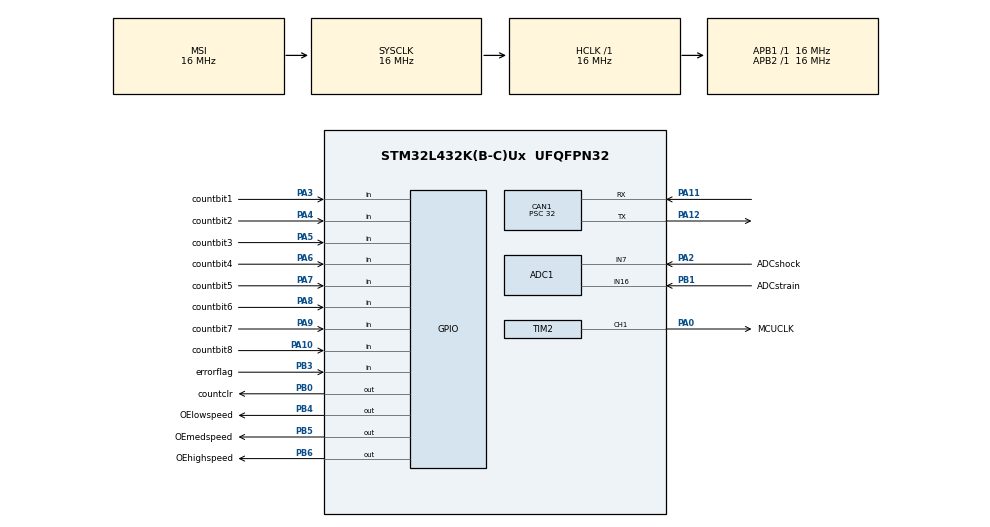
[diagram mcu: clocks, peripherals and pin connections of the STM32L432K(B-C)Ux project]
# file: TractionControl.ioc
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Mcu.Family=STM32L4
RCC.CortexFreq_Value=16000000
PA0.GPIO_Label=MCUCLK
PA11.Mode=Master
PA6.GPIO_Label=countbit4
PB0.GPIO_Label=countclr
PB6.GPIO_Label=OEhighspeed
ProjectManager.StackSize=0x400
PB3\ (JTDO-TRACESWO).Signal=GPIO_Input
SH.ADCx_IN16.0=ADC1_IN16,IN16-Single-Ended
PA14\ (JTCK-SWCLK).Signal=SYS_JTCK-SWCLK
PA12.Signal=CAN1_TX
TIM15.Prescaler=10000
RCC.HCLKFreq_Value=16000000
RCC.APB2TimFreq_Value=16000000
PB6.Signal=GPIO_Output
RCC.AHBFreq_Value=16000000
ADC1.Channel-0\#ChannelRegularConversion=ADC_CHANNEL_7
RCC.HSE_VALUE=8000000
VP_SYS_VS_tim1.Mode=TIM1
PB1.GPIO_Label=ADCstrain
PA10.GPIO_Label=countbit8
PA8.Signal=GPIO_Input
TIM2.Channel-PWM\ Generation1\ CH1=TIM_CHANNEL_1
ADC1.SamplingTime-0\#ChannelRegularConversion=ADC_SAMPLETIME_2CYCLES_5
PA0.Signal=S_TIM2_CH1
CAN1.Prescaler=32
Mcu.Package=UFQFPN32
PA6.Signal=GPIO_Input
PB1.Signal=ADCx_IN16
NVIC.TimeBase=TIM1_UP_TIM16_IRQn
PA2.GPIO_Label=ADCshock
NVIC.TimeBaseIP=TIM1
PA10.Signal=GPIO_Input
PB5.GPIO_Label=OEmedspeed
RCC.APB1TimFreq_Value=16000000
PA13\ (JTMS-SWDIO).Signal=SYS_JTMS-SWDIO
PA4.GPIO_Label=countbit2
RCC.MSIClockRange=RCC_MSIRANGE_8
RCC.HSI48_VALUE=48000000
PA3.Signal=GPIO_Input
CAN1.CalculateTimeQuantum=2000.0
RCC.MSI_VALUE=16000000
PA14\ (JTCK-SWCLK).Mode=Serial_Wire
SH.S_TIM2_CH1.0=TIM2_CH1,PWM Generation1 CH1
ADC1.Rank-0\#ChannelRegularConversion=1
ADC1.OffsetNumber-0\#ChannelRegularConversion=ADC_OFFSET_NONE
PA9.GPIO_Label=countbit7
PB3\ (JTDO-TRACESWO).GPIO_Label=errorflag
TIM2.Pulse-PWM\ Generation1\ CH1=1
PA8.GPIO_Label=countbit6
CAN1.BS2=CAN_BS2_2TQ
ProjectManager.TargetToolchain=SW4STM32
SH.ADCx_IN7.0=ADC1_IN7,IN7-Single-Ended
PA9.Signal=GPIO_Input
RCC.USBFreq_Value=64000000
RCC.LSE_VALUE=32768
PA5.Signal=GPIO_Input
NVIC.TIM1_BRK_TIM15_IRQn=true\:0\:0\:false\:false\:true\:true\:true
board=custom
RCC.VCOOutputFreq_Value=128000000
RCC.APB2Freq_Value=16000000
RCC.ADCFreq_Value=64000000
TIM2.Period=1
Mcu.Name=STM32L432K(B-C)Ux
PA2.Signal=ADCx_IN7
CAN1.SJW=CAN_SJW_2TQ
PA13\ (JTMS-SWDIO).Mode=Serial_Wire
PA4.Signal=GPIO_Input
RCC.SYSCLKFreq_VALUE=16000000
PB5.Signal=GPIO_Output
PA7.GPIO_Label=countbit5
ADC1.master=1
PA12.Mode=Master
PA5.GPIO_Label=countbit3
PA11.Signal=CAN1_RX
VP_TIM15_VS_ClockSourceINT.Mode=Internal
ProjectManager.HeapSize=0x200
RCC.HSI_VALUE=16000000
NVIC.TIM1_UP_TIM16_IRQn=true\:0\:0\:false\:false\:true\:false\:true
NVIC.PriorityGroup=NVIC_PRIORITYGROUP_4
ADC1.NbrOfConversionFlag=1
PB4\ (NJTRST).GPIO_Label=OElowspeed
RCC.APB1Freq_Value=16000000
PB0.Signal=GPIO_Output
PA3.GPIO_Label=countbit1
PA7.Signal=GPIO_Input
PB4\ (NJTRST).Signal=GPIO_Output

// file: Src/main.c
/* USER CODE BEGIN Header */
/**
  ******************************************************************************
  * @file           : main.c
  * @brief          : Main program body
  ******************************************************************************
  ** This notice applies to any and all portions of this file
  * that are not between comment pairs USER CODE BEGIN and
  * USER CODE END. Other portions of this file, whether
  * inserted by the user or by software development tools
  * are owned by their respective copyright owners.
  *
  * COPYRIGHT(c) 2020 STMicroelectronics
  *
  * Redistribution and use in source and binary forms, with or without modification,
  * are permitted provided that the following conditions are met:
  *   1. Redistributions of source code must retain the above copyright notice,
  *      this list of conditions and the following disclaimer.
  *   2. Redistributions in binary form must reproduce the above copyright notice,
  *      this list of conditions and the following disclaimer in the documentation
  *      and/or other materials provided with the distribution.
  *   3. Neither the name of STMicroelectronics nor the names of its contributors
  *      may be used to endorse or promote products derived from this software
  *      without specific prior written permission.
  *
  * THIS SOFTWARE IS PROVIDED BY THE COPYRIGHT HOLDERS AND CONTRIBUTORS "AS IS"
  * AND ANY EXPRESS OR IMPLIED WARRANTIES, INCLUDING, BUT NOT LIMITED TO, THE
  * IMPLIED WARRANTIES OF MERCHANTABILITY AND FITNESS FOR A PARTICULAR PURPOSE ARE
  * DISCLAIMED. IN NO EVENT SHALL THE COPYRIGHT HOLDER OR CONTRIBUTORS BE LIABLE
  * FOR ANY DIRECT, INDIRECT, INCIDENTAL, SPECIAL, EXEMPLARY, OR CONSEQUENTIAL
  * DAMAGES (INCLUDING, BUT NOT LIMITED TO, PROCUREMENT OF SUBSTITUTE GOODS OR
  * SERVICES; LOSS OF USE, DATA, OR PROFITS; OR BUSINESS INTERRUPTION) HOWEVER
  * CAUSED AND ON ANY THEORY OF LIABILITY, WHETHER IN CONTRACT, STRICT LIABILITY,
  * OR TORT (INCLUDING NEGLIGENCE OR OTHERWISE) ARISING IN ANY WAY OUT OF THE USE
  * OF THIS SOFTWARE, EVEN IF ADVISED OF THE POSSIBILITY OF SUCH DAMAGE.
  *
  ******************************************************************************
  */
/* USER CODE END Header */

#include "main.h"

/* USER CODE BEGIN Includes */
#include "tc.h"
/* USER CODE END Includes */

ADC_HandleTypeDef hadc1;

CAN_HandleTypeDef hcan1;

TIM_HandleTypeDef htim2;
TIM_HandleTypeDef htim15;

void SystemClock_Config(void);
static void MX_GPIO_Init(void);
static void MX_TIM2_Init(void);
static void MX_CAN1_Init(void);
static void MX_ADC1_Init(void);
static void MX_TIM15_Init(void);

int main(void)
{

  /* MCU Configuration--------------------------------------------------------*/

  /* Reset of all peripherals, Initializes the Flash interface and the Systick. */
  HAL_Init();

  /* Configure the system clock */
  SystemClock_Config();

  /* Initialize all configured peripherals */
  MX_GPIO_Init();
  MX_TIM2_Init();
  MX_CAN1_Init();
  MX_ADC1_Init();
  MX_TIM15_Init();
  /* USER CODE BEGIN 2 */

  // Clear the binary counter
  HAL_GPIO_WritePin(countclr_GPIO_Port, countclr_Pin, 1);
  HAL_Delay(2);
  HAL_GPIO_WritePin(countclr_GPIO_Port, countclr_Pin, 0);
  HAL_GPIO_WritePin(OElowspeed_GPIO_Port, OElowspeed_Pin, 1);

  // Initialize and start timer 2
  tim2Setup();
  tim7Setup();
  tcLoop();
  /* USER CODE END 2 */

  /* Infinite loop */
  /* USER CODE BEGIN WHILE */
  while (1)
  {
    // We will just be chilling here until timer 15 throws an interrupt and tcLoop() handles it
    /* USER CODE END WHILE */

  }
}

void SystemClock_Config(void)
{
  RCC_OscInitTypeDef RCC_OscInitStruct = {0};
  RCC_ClkInitTypeDef RCC_ClkInitStruct = {0};
  RCC_PeriphCLKInitTypeDef PeriphClkInit = {0};

  /**Initializes the CPU, AHB and APB busses clocks
  */
  RCC_OscInitStruct.OscillatorType = RCC_OSCILLATORTYPE_MSI;
  RCC_OscInitStruct.MSIState = RCC_MSI_ON;
  RCC_OscInitStruct.MSICalibrationValue = 0;
  RCC_OscInitStruct.MSIClockRange = RCC_MSIRANGE_8;
  RCC_OscInitStruct.PLL.PLLState = RCC_PLL_NONE;
  if (HAL_RCC_OscConfig(&RCC_OscInitStruct) != HAL_OK)
  {
    Error_Handler();
  }
  /**Initializes the CPU, AHB and APB busses clocks
  */
  RCC_ClkInitStruct.ClockType = RCC_CLOCKTYPE_HCLK|RCC_CLOCKTYPE_SYSCLK
                              |RCC_CLOCKTYPE_PCLK1|RCC_CLOCKTYPE_PCLK2;
  RCC_ClkInitStruct.SYSCLKSource = RCC_SYSCLKSOURCE_MSI;
  RCC_ClkInitStruct.AHBCLKDivider = RCC_SYSCLK_DIV1;
  RCC_ClkInitStruct.APB1CLKDivider = RCC_HCLK_DIV1;
  RCC_ClkInitStruct.APB2CLKDivider = RCC_HCLK_DIV1;

  if (HAL_RCC_ClockConfig(&RCC_ClkInitStruct, FLASH_LATENCY_0) != HAL_OK)
  {
    Error_Handler();
  }
  PeriphClkInit.PeriphClockSelection = RCC_PERIPHCLK_ADC;
  PeriphClkInit.AdcClockSelection = RCC_ADCCLKSOURCE_PLLSAI1;
  PeriphClkInit.PLLSAI1.PLLSAI1Source = RCC_PLLSOURCE_MSI;
  PeriphClkInit.PLLSAI1.PLLSAI1M = 1;
  PeriphClkInit.PLLSAI1.PLLSAI1N = 8;
  PeriphClkInit.PLLSAI1.PLLSAI1P = RCC_PLLP_DIV7;
  PeriphClkInit.PLLSAI1.PLLSAI1Q = RCC_PLLQ_DIV2;
  PeriphClkInit.PLLSAI1.PLLSAI1R = RCC_PLLR_DIV2;
  PeriphClkInit.PLLSAI1.PLLSAI1ClockOut = RCC_PLLSAI1_ADC1CLK;
  if (HAL_RCCEx_PeriphCLKConfig(&PeriphClkInit) != HAL_OK)
  {
    Error_Handler();
  }
  /**Configure the main internal regulator output voltage
  */
  if (HAL_PWREx_ControlVoltageScaling(PWR_REGULATOR_VOLTAGE_SCALE1) != HAL_OK)
  {
    Error_Handler();
  }
}

static void MX_ADC1_Init(void)
{

  ADC_ChannelConfTypeDef sConfig = {0};

  /**Common config
  */
  hadc1.Instance = ADC1;
  hadc1.Init.ClockPrescaler = ADC_CLOCK_ASYNC_DIV1;
  hadc1.Init.Resolution = ADC_RESOLUTION_12B;
  hadc1.Init.DataAlign = ADC_DATAALIGN_RIGHT;
  hadc1.Init.ScanConvMode = ADC_SCAN_DISABLE;
  hadc1.Init.EOCSelection = ADC_EOC_SINGLE_CONV;
  hadc1.Init.LowPowerAutoWait = DISABLE;
  hadc1.Init.ContinuousConvMode = DISABLE;
  hadc1.Init.NbrOfConversion = 1;
  hadc1.Init.DiscontinuousConvMode = DISABLE;
  hadc1.Init.ExternalTrigConv = ADC_SOFTWARE_START;
  hadc1.Init.ExternalTrigConvEdge = ADC_EXTERNALTRIGCONVEDGE_NONE;
  hadc1.Init.DMAContinuousRequests = DISABLE;
  hadc1.Init.Overrun = ADC_OVR_DATA_PRESERVED;
  hadc1.Init.OversamplingMode = DISABLE;
  if (HAL_ADC_Init(&hadc1) != HAL_OK)
  {
    Error_Handler();
  }
  /**Configure Regular Channel
  */
  sConfig.Channel = ADC_CHANNEL_7;
  sConfig.Rank = ADC_REGULAR_RANK_1;
  sConfig.SamplingTime = ADC_SAMPLETIME_2CYCLES_5;
  sConfig.SingleDiff = ADC_SINGLE_ENDED;
  sConfig.OffsetNumber = ADC_OFFSET_NONE;
  sConfig.Offset = 0;
  if (HAL_ADC_ConfigChannel(&hadc1, &sConfig) != HAL_OK)
  {
    Error_Handler();
  }

}

static void MX_CAN1_Init(void)
{

  hcan1.Instance = CAN1;
  hcan1.Init.Prescaler = 32;
  hcan1.Init.Mode = CAN_MODE_NORMAL;
  hcan1.Init.SyncJumpWidth = CAN_SJW_2TQ;
  hcan1.Init.TimeSeg1 = CAN_BS1_1TQ;
  hcan1.Init.TimeSeg2 = CAN_BS2_2TQ;
  hcan1.Init.TimeTriggeredMode = DISABLE;
  hcan1.Init.AutoBusOff = DISABLE;
  hcan1.Init.AutoWakeUp = DISABLE;
  hcan1.Init.AutoRetransmission = DISABLE;
  hcan1.Init.ReceiveFifoLocked = DISABLE;
  hcan1.Init.TransmitFifoPriority = DISABLE;
  if (HAL_CAN_Init(&hcan1) != HAL_OK)
  {
    Error_Handler();
  }

}

static void MX_TIM2_Init(void)
{

  TIM_MasterConfigTypeDef sMasterConfig = {0};
  TIM_OC_InitTypeDef sConfigOC = {0};

  htim2.Instance = TIM2;
  htim2.Init.Prescaler = 0;
  htim2.Init.CounterMode = TIM_COUNTERMODE_UP;
  htim2.Init.Period = 1;
  htim2.Init.ClockDivision = TIM_CLOCKDIVISION_DIV1;
  htim2.Init.AutoReloadPreload = TIM_AUTORELOAD_PRELOAD_DISABLE;
  if (HAL_TIM_PWM_Init(&htim2) != HAL_OK)
  {
    Error_Handler();
  }
  sMasterConfig.MasterOutputTrigger = TIM_TRGO_RESET;
  sMasterConfig.MasterSlaveMode = TIM_MASTERSLAVEMODE_DISABLE;
  if (HAL_TIMEx_MasterConfigSynchronization(&htim2, &sMasterConfig) != HAL_OK)
  {
    Error_Handler();
  }
  sConfigOC.OCMode = TIM_OCMODE_PWM1;
  sConfigOC.Pulse = 1;
  sConfigOC.OCPolarity = TIM_OCPOLARITY_HIGH;
  sConfigOC.OCFastMode = TIM_OCFAST_DISABLE;
  if (HAL_TIM_PWM_ConfigChannel(&htim2, &sConfigOC, TIM_CHANNEL_1) != HAL_OK)
  {
    Error_Handler();
  }
  HAL_TIM_MspPostInit(&htim2);

}

static void MX_TIM15_Init(void)
{

  TIM_ClockConfigTypeDef sClockSourceConfig = {0};
  TIM_MasterConfigTypeDef sMasterConfig = {0};

  htim15.Instance = TIM15;
  htim15.Init.Prescaler = 10000;
  htim15.Init.CounterMode = TIM_COUNTERMODE_UP;
  htim15.Init.Period = 0;
  htim15.Init.ClockDivision = TIM_CLOCKDIVISION_DIV1;
  htim15.Init.RepetitionCounter = 0;
  htim15.Init.AutoReloadPreload = TIM_AUTORELOAD_PRELOAD_DISABLE;
  if (HAL_TIM_Base_Init(&htim15) != HAL_OK)
  {
    Error_Handler();
  }
  sClockSourceConfig.ClockSource = TIM_CLOCKSOURCE_INTERNAL;
  if (HAL_TIM_ConfigClockSource(&htim15, &sClockSourceConfig) != HAL_OK)
  {
    Error_Handler();
  }
  sMasterConfig.MasterOutputTrigger = TIM_TRGO_RESET;
  sMasterConfig.MasterSlaveMode = TIM_MASTERSLAVEMODE_DISABLE;
  if (HAL_TIMEx_MasterConfigSynchronization(&htim15, &sMasterConfig) != HAL_OK)
  {
    Error_Handler();
  }

}

static void MX_GPIO_Init(void)
{
  GPIO_InitTypeDef GPIO_InitStruct = {0};

  /* GPIO Ports Clock Enable */
  __HAL_RCC_GPIOA_CLK_ENABLE();
  __HAL_RCC_GPIOB_CLK_ENABLE();

  /*Configure GPIO pin Output Level */
  HAL_GPIO_WritePin(GPIOB, countclr_Pin|OElowspeed_Pin|OEmedspeed_Pin|OEhighspeed_Pin, GPIO_PIN_RESET);

  /*Configure GPIO pins : countbit1_Pin countbit2_Pin countbit3_Pin countbit4_Pin
                           countbit5_Pin countbit6_Pin countbit7_Pin countbit8_Pin */
  GPIO_InitStruct.Pin = countbit1_Pin|countbit2_Pin|countbit3_Pin|countbit4_Pin
                          |countbit5_Pin|countbit6_Pin|countbit7_Pin|countbit8_Pin;
  GPIO_InitStruct.Mode = GPIO_MODE_INPUT;
  GPIO_InitStruct.Pull = GPIO_NOPULL;
  HAL_GPIO_Init(GPIOA, &GPIO_InitStruct);

  /*Configure GPIO pins : countclr_Pin OElowspeed_Pin OEmedspeed_Pin OEhighspeed_Pin */
  GPIO_InitStruct.Pin = countclr_Pin|OElowspeed_Pin|OEmedspeed_Pin|OEhighspeed_Pin;
  GPIO_InitStruct.Mode = GPIO_MODE_OUTPUT_PP;
  GPIO_InitStruct.Pull = GPIO_NOPULL;
  GPIO_InitStruct.Speed = GPIO_SPEED_FREQ_LOW;
  HAL_GPIO_Init(GPIOB, &GPIO_InitStruct);

  /*Configure GPIO pin : errorflag_Pin */
  GPIO_InitStruct.Pin = errorflag_Pin;
  GPIO_InitStruct.Mode = GPIO_MODE_INPUT;
  GPIO_InitStruct.Pull = GPIO_NOPULL;
  HAL_GPIO_Init(errorflag_GPIO_Port, &GPIO_InitStruct);

}

void HAL_TIM_PeriodElapsedCallback(TIM_HandleTypeDef *htim)
{
  if (htim->Instance == TIM1) {
    HAL_IncTick();
  }
}

void Error_Handler(void)
{
}

/************************ (C) COPYRIGHT STMicroelectronics *****END OF FILE****/
